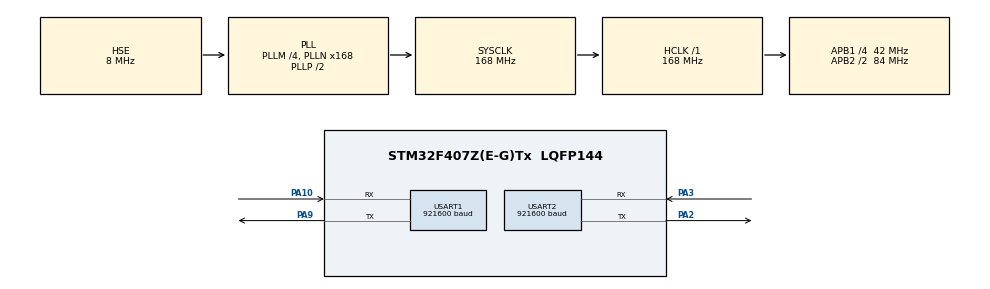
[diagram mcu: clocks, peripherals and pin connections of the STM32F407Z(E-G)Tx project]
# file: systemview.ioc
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FREERTOS.Tasks01=defaultTask,0,1024,StartDefaultTask,Default,NULL,Dynamic,NULL,NULL;myTask02,-3,1024,StartTask02,Default,NULL,Dynamic,NULL,NULL
FREERTOS.configTOTAL_HEAP_SIZE=51200
Mcu.Family=STM32F4
Mcu.Name=STM32F407Z(E-G)Tx
Mcu.Package=LQFP144
NVIC.PriorityGroup=NVIC_PRIORITYGROUP_4
NVIC.USART1_IRQn=true\:5\:0\:false\:false\:true\:true\:true\:true
NVIC.USART2_IRQn=true\:5\:0\:false\:false\:true\:true\:true\:true
PA10.Mode=Asynchronous
PA10.Signal=USART1_RX
PA13.Mode=JTAG_4_pins
PA13.Signal=SYS_JTMS-SWDIO
PA14.Mode=JTAG_4_pins
PA14.Signal=SYS_JTCK-SWCLK
PA15.Mode=JTAG_4_pins
PA15.Signal=SYS_JTDI
PA2.Mode=Asynchronous
PA2.Signal=USART2_TX
PA3.Mode=Asynchronous
PA3.Signal=USART2_RX
PA9.Mode=Asynchronous
PA9.Signal=USART1_TX
PB3.Mode=JTAG_4_pins
PB3.Signal=SYS_JTDO-SWO
PH0-OSC_IN.Mode=HSE-External-Oscillator
PH0-OSC_IN.Signal=RCC_OSC_IN
PH1-OSC_OUT.Mode=HSE-External-Oscillator
PH1-OSC_OUT.Signal=RCC_OSC_OUT
ProjectManager.HeapSize=0x200
ProjectManager.StackSize=0x400
ProjectManager.TargetToolchain=MDK-ARM V5.27
RCC.48MHZClocksFreq_Value=84000000
RCC.AHBFreq_Value=168000000
RCC.APB1CLKDivider=RCC_HCLK_DIV4
RCC.APB1Freq_Value=42000000
RCC.APB1TimFreq_Value=84000000
RCC.APB2CLKDivider=RCC_HCLK_DIV2
RCC.APB2Freq_Value=84000000
RCC.APB2TimFreq_Value=168000000
RCC.CortexFreq_Value=168000000
RCC.HCLKFreq_Value=168000000
RCC.HSE_VALUE=8000000
RCC.HSI_VALUE=16000000
RCC.LSE_VALUE=32768
RCC.PLLM=4
RCC.PLLN=168
RCC.PLLSourceVirtual=RCC_PLLSOURCE_HSE
RCC.SYSCLKFreq_VALUE=168000000
RCC.SYSCLKSource=RCC_SYSCLKSOURCE_PLLCLK
RCC.VCOOutputFreq_Value=336000000
USART1.BaudRate=921600
USART1.VirtualMode=VM_ASYNC
USART2.BaudRate=921600
USART2.VirtualMode=VM_ASYNC
VP_FREERTOS_VS_CMSIS_V1.Mode=CMSIS_V1
board=custom

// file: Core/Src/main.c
/* USER CODE BEGIN Header */
/**
  ******************************************************************************
  * @file           : main.c
  * @brief          : Main program body
  ******************************************************************************
  * @attention
  *
  * <h2><center>&copy; Copyright (c) 2021 STMicroelectronics.
  * All rights reserved.</center></h2>
  *
  * This software component is licensed by ST under Ultimate Liberty license
  * SLA0044, the "License"; You may not use this file except in compliance with
  * the License. You may obtain a copy of the License at:
  *                             www.st.com/SLA0044
  *
  ******************************************************************************
  */
/* USER CODE END Header */
#include "main.h"
#include "cmsis_os.h"
#include "systemview_serial_port.h"

UART_HandleTypeDef huart1;
UART_HandleTypeDef huart2;

osThreadId defaultTaskHandle;
osThreadId myTask02Handle;

void SystemClock_Config(void);
static void MX_GPIO_Init(void);
static void MX_USART1_UART_Init(void);
static void MX_USART2_UART_Init(void);
void StartDefaultTask(void const *argument);
void StartTask02(void const *argument);

int main(void)
{

    /* MCU Configuration--------------------------------------------------------*/

    /* Reset of all peripherals, Initializes the Flash interface and the Systick. */
    HAL_Init();

    /* Configure the system clock */
    SystemClock_Config();

    /* Initialize all configured peripherals */
    MX_GPIO_Init();
    MX_USART1_UART_Init();
    MX_USART2_UART_Init();

    /* Create the thread(s) */
    /* definition and creation of defaultTask */
    osThreadDef(defaultTask, StartDefaultTask, osPriorityNormal, 0, 1024);
    defaultTaskHandle = osThreadCreate(osThread(defaultTask), NULL);

    /* definition and creation of myTask02 */
    osThreadDef(myTask02, StartTask02, osPriorityIdle, 0, 1024);
    myTask02Handle = osThreadCreate(osThread(myTask02), NULL);

    systemview_uart_recorder_init();
    /* Start scheduler */
    osKernelStart();

    /* We should never get here as control is now taken by the scheduler */
    /* Infinite loop */
    while (1)
    {

    }
}

void SystemClock_Config(void)
{
    RCC_OscInitTypeDef RCC_OscInitStruct = {0};
    RCC_ClkInitTypeDef RCC_ClkInitStruct = {0};

    /** Configure the main internal regulator output voltage
  */
    __HAL_RCC_PWR_CLK_ENABLE();
    __HAL_PWR_VOLTAGESCALING_CONFIG(PWR_REGULATOR_VOLTAGE_SCALE1);
    /** Initializes the RCC Oscillators according to the specified parameters
  * in the RCC_OscInitTypeDef structure.
  */
    RCC_OscInitStruct.OscillatorType = RCC_OSCILLATORTYPE_HSE;
    RCC_OscInitStruct.HSEState = RCC_HSE_ON;
    RCC_OscInitStruct.PLL.PLLState = RCC_PLL_ON;
    RCC_OscInitStruct.PLL.PLLSource = RCC_PLLSOURCE_HSE;
    RCC_OscInitStruct.PLL.PLLM = 4;
    RCC_OscInitStruct.PLL.PLLN = 168;
    RCC_OscInitStruct.PLL.PLLP = RCC_PLLP_DIV2;
    RCC_OscInitStruct.PLL.PLLQ = 4;
    if (HAL_RCC_OscConfig(&RCC_OscInitStruct) != HAL_OK)
    {
        Error_Handler();
    }
    /** Initializes the CPU, AHB and APB buses clocks
  */
    RCC_ClkInitStruct.ClockType = RCC_CLOCKTYPE_HCLK | RCC_CLOCKTYPE_SYSCLK | RCC_CLOCKTYPE_PCLK1 | RCC_CLOCKTYPE_PCLK2;
    RCC_ClkInitStruct.SYSCLKSource = RCC_SYSCLKSOURCE_PLLCLK;
    RCC_ClkInitStruct.AHBCLKDivider = RCC_SYSCLK_DIV1;
    RCC_ClkInitStruct.APB1CLKDivider = RCC_HCLK_DIV4;
    RCC_ClkInitStruct.APB2CLKDivider = RCC_HCLK_DIV2;

    if (HAL_RCC_ClockConfig(&RCC_ClkInitStruct, FLASH_LATENCY_5) != HAL_OK)
    {
        Error_Handler();
    }
}

static void MX_USART1_UART_Init(void)
{

    huart1.Instance = USART1;
    huart1.Init.BaudRate = 921600;
    huart1.Init.WordLength = UART_WORDLENGTH_8B;
    huart1.Init.StopBits = UART_STOPBITS_1;
    huart1.Init.Parity = UART_PARITY_NONE;
    huart1.Init.Mode = UART_MODE_TX_RX;
    huart1.Init.HwFlowCtl = UART_HWCONTROL_NONE;
    huart1.Init.OverSampling = UART_OVERSAMPLING_16;
    if (HAL_UART_Init(&huart1) != HAL_OK)
    {
        Error_Handler();
    }
    /* USER CODE BEGIN USART1_Init 2 */
    __HAL_UART_CLEAR_FLAG(&huart1, USART_SR_RXNE);
    __HAL_UART_ENABLE_IT(&huart1, UART_IT_RXNE);
    /* USER CODE END USART1_Init 2 */
}

static void MX_USART2_UART_Init(void)
{

    huart2.Instance = USART2;
    huart2.Init.BaudRate = 921600;
    huart2.Init.WordLength = UART_WORDLENGTH_8B;
    huart2.Init.StopBits = UART_STOPBITS_1;
    huart2.Init.Parity = UART_PARITY_NONE;
    huart2.Init.Mode = UART_MODE_TX_RX;
    huart2.Init.HwFlowCtl = UART_HWCONTROL_NONE;
    huart2.Init.OverSampling = UART_OVERSAMPLING_16;
    if (HAL_UART_Init(&huart2) != HAL_OK)
    {
        Error_Handler();
    }
}

static void MX_GPIO_Init(void)
{

    /* GPIO Ports Clock Enable */
    __HAL_RCC_GPIOH_CLK_ENABLE();
    __HAL_RCC_GPIOA_CLK_ENABLE();
    __HAL_RCC_GPIOB_CLK_ENABLE();
}

void StartDefaultTask(void const *argument)
{
    /* USER CODE BEGIN 5 */
    /* Infinite loop */
    for (;;)
    {
        //   HAL_UART_Transmit(&huart1, "StartDefaultTask", strlen("StartDefaultTask"), 10);
        for (size_t i = 0; i < 100000; i++)
        {
            __NOP();
        }
        osDelay(1000);
    }
    /* USER CODE END 5 */
}

void StartTask02(void const *argument)
{
    /* USER CODE BEGIN StartTask02 */
    /* Infinite loop */
    for (;;)
    {
        //   HAL_UART_Transmit(&huart1, "StartTask02", strlen("StartTask02"), 10);
        for (size_t i = 0; i < 50000; i++)
        {
            __NOP();
        }
        osDelay(1000);
    }
    /* USER CODE END StartTask02 */
}

void Error_Handler(void)
{
    __disable_irq();
    while (1)
    {
    }
}

/************************ (C) COPYRIGHT STMicroelectronics *****END OF FILE****/
